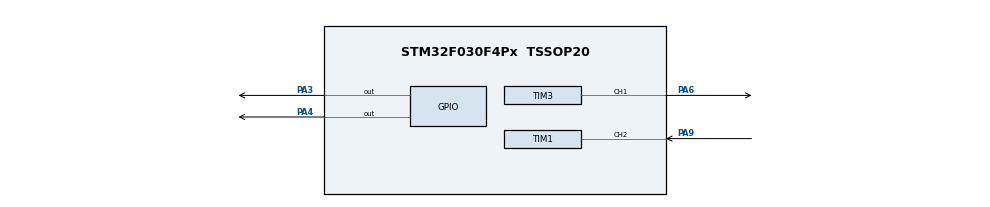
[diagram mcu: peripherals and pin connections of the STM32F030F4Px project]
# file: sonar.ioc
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Mcu.Family=STM32F0
Mcu.Name=STM32F030F4Px
Mcu.Package=TSSOP20
NVIC.TIM1_CC_IRQn=true\:0\:0\:false\:false\:true\:true
NVIC.TIM3_IRQn=true\:0\:0\:false\:false\:true\:true
PA3.Signal=GPIO_Output
PA4.Signal=GPIO_Output
PA6.Signal=S_TIM3_CH1
PA9.Signal=S_TIM1_CH2
ProjectManager.HeapSize=0x200
ProjectManager.StackSize=0x400
ProjectManager.TargetToolchain=SW4STM32
SH.S_TIM1_CH2.0=TIM1_CH2,PWM_Input_2
SH.S_TIM3_CH1.0=TIM3_CH1,PWM Generation1 CH1
TIM1.ICPolarity_1=TIM_INPUTCHANNELPOLARITY_FALLING
TIM1.Period=60000
TIM1.Prescaler=8
TIM3.Channel-PWM\ Generation1\ CH1=TIM_CHANNEL_1
TIM3.Period=40000
TIM3.Prescaler=8
TIM3.Pulse-PWM\ Generation1\ CH1=10
board=sonar

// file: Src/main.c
/**
  ******************************************************************************
  * File Name          : main.c
  * Description        : Main program body
  ******************************************************************************
  ** This notice applies to any and all portions of this file
  * that are not between comment pairs USER CODE BEGIN and
  * USER CODE END. Other portions of this file, whether
  * inserted by the user or by software development tools
  * are owned by their respective copyright owners.
  *
  * COPYRIGHT(c) 2017 STMicroelectronics
  *
  * Redistribution and use in source and binary forms, with or without modification,
  * are permitted provided that the following conditions are met:
  *   1. Redistributions of source code must retain the above copyright notice,
  *      this list of conditions and the following disclaimer.
  *   2. Redistributions in binary form must reproduce the above copyright notice,
  *      this list of conditions and the following disclaimer in the documentation
  *      and/or other materials provided with the distribution.
  *   3. Neither the name of STMicroelectronics nor the names of its contributors
  *      may be used to endorse or promote products derived from this software
  *      without specific prior written permission.
  *
  * THIS SOFTWARE IS PROVIDED BY THE COPYRIGHT HOLDERS AND CONTRIBUTORS "AS IS"
  * AND ANY EXPRESS OR IMPLIED WARRANTIES, INCLUDING, BUT NOT LIMITED TO, THE
  * IMPLIED WARRANTIES OF MERCHANTABILITY AND FITNESS FOR A PARTICULAR PURPOSE ARE
  * DISCLAIMED. IN NO EVENT SHALL THE COPYRIGHT HOLDER OR CONTRIBUTORS BE LIABLE
  * FOR ANY DIRECT, INDIRECT, INCIDENTAL, SPECIAL, EXEMPLARY, OR CONSEQUENTIAL
  * DAMAGES (INCLUDING, BUT NOT LIMITED TO, PROCUREMENT OF SUBSTITUTE GOODS OR
  * SERVICES; LOSS OF USE, DATA, OR PROFITS; OR BUSINESS INTERRUPTION) HOWEVER
  * CAUSED AND ON ANY THEORY OF LIABILITY, WHETHER IN CONTRACT, STRICT LIABILITY,
  * OR TORT (INCLUDING NEGLIGENCE OR OTHERWISE) ARISING IN ANY WAY OUT OF THE USE
  * OF THIS SOFTWARE, EVEN IF ADVISED OF THE POSSIBILITY OF SUCH DAMAGE.
  *
  ******************************************************************************
  */

#include "main.h"
#include "stm32f0xx_hal.h"

TIM_HandleTypeDef htim1;
TIM_HandleTypeDef htim3;

/* USER CODE BEGIN PV */
/* Private variables ---------------------------------------------------------*/
__IO uint32_t sensorValue = 0;
/* USER CODE END PV */

void SystemClock_Config(void);
static void MX_GPIO_Init(void);
static void MX_TIM3_Init(void);
static void MX_TIM1_Init(void);

void HAL_TIM_MspPostInit(TIM_HandleTypeDef *htim);

/* USER CODE BEGIN PFP */
/* Private function prototypes -----------------------------------------------*/

/* USER CODE END PFP */

/* USER CODE BEGIN 0 */
void HAL_TIM_IC_CaptureCallback(TIM_HandleTypeDef *htim)
{
	if(htim->Channel==HAL_TIM_ACTIVE_CHANNEL_1) {
		sensorValue=HAL_TIM_ReadCapturedValue(htim, TIM_CHANNEL_1);
	}
}
/* USER CODE END 0 */

int main(void)
{

  /* MCU Configuration----------------------------------------------------------*/

  /* Reset of all peripherals, Initializes the Flash interface and the Systick. */
  HAL_Init();

  /* Configure the system clock */
  SystemClock_Config();

  /* Initialize all configured peripherals */
  MX_GPIO_Init();
  MX_TIM3_Init();
  MX_TIM1_Init();

  /* USER CODE BEGIN 2 */
  HAL_TIM_PWM_Start(&htim3, TIM_CHANNEL_1);

  HAL_TIM_IC_Start_IT(&htim1,TIM_CHANNEL_1);
  HAL_TIM_IC_Start_IT(&htim1,TIM_CHANNEL_2);
  /* USER CODE END 2 */

  /* Infinite loop */
  /* USER CODE BEGIN WHILE */
  uint32_t tick_start=HAL_GetTick();

  while (1)
  {
	  uint32_t distance = sensorValue/58;

	  if(distance<100 && HAL_GetTick()-tick_start>distance*10) {
		  HAL_GPIO_TogglePin(GPIOA,GPIO_PIN_3);
		  tick_start=HAL_GetTick();
	  }

  /* USER CODE END WHILE */

  }

}

/** System Clock Configuration
*/
void SystemClock_Config(void)
{

  RCC_OscInitTypeDef RCC_OscInitStruct;
  RCC_ClkInitTypeDef RCC_ClkInitStruct;

    /**Initializes the CPU, AHB and APB busses clocks
    */
  RCC_OscInitStruct.OscillatorType = RCC_OSCILLATORTYPE_HSI;
  RCC_OscInitStruct.HSIState = RCC_HSI_ON;
  RCC_OscInitStruct.HSICalibrationValue = 16;
  RCC_OscInitStruct.PLL.PLLState = RCC_PLL_NONE;
  if (HAL_RCC_OscConfig(&RCC_OscInitStruct) != HAL_OK)
  {
    _Error_Handler(__FILE__, __LINE__);
  }

    /**Initializes the CPU, AHB and APB busses clocks
    */
  RCC_ClkInitStruct.ClockType = RCC_CLOCKTYPE_HCLK|RCC_CLOCKTYPE_SYSCLK
                              |RCC_CLOCKTYPE_PCLK1;
  RCC_ClkInitStruct.SYSCLKSource = RCC_SYSCLKSOURCE_HSI;
  RCC_ClkInitStruct.AHBCLKDivider = RCC_SYSCLK_DIV1;
  RCC_ClkInitStruct.APB1CLKDivider = RCC_HCLK_DIV1;

  if (HAL_RCC_ClockConfig(&RCC_ClkInitStruct, FLASH_LATENCY_0) != HAL_OK)
  {
    _Error_Handler(__FILE__, __LINE__);
  }

    /**Configure the Systick interrupt time
    */
  HAL_SYSTICK_Config(HAL_RCC_GetHCLKFreq()/1000);

    /**Configure the Systick
    */
  HAL_SYSTICK_CLKSourceConfig(SYSTICK_CLKSOURCE_HCLK);

  /* SysTick_IRQn interrupt configuration */
  HAL_NVIC_SetPriority(SysTick_IRQn, 0, 0);
}

/* TIM1 init function */
static void MX_TIM1_Init(void)
{

  TIM_SlaveConfigTypeDef sSlaveConfig;
  TIM_IC_InitTypeDef sConfigIC;
  TIM_MasterConfigTypeDef sMasterConfig;

  htim1.Instance = TIM1;
  htim1.Init.Prescaler = 8;
  htim1.Init.CounterMode = TIM_COUNTERMODE_UP;
  htim1.Init.Period = 60000;
  htim1.Init.ClockDivision = TIM_CLOCKDIVISION_DIV1;
  htim1.Init.RepetitionCounter = 0;
  htim1.Init.AutoReloadPreload = TIM_AUTORELOAD_PRELOAD_DISABLE;
  if (HAL_TIM_IC_Init(&htim1) != HAL_OK)
  {
    _Error_Handler(__FILE__, __LINE__);
  }

  sSlaveConfig.SlaveMode = TIM_SLAVEMODE_RESET;
  sSlaveConfig.InputTrigger = TIM_TS_TI2FP2;
  sSlaveConfig.TriggerPolarity = TIM_INPUTCHANNELPOLARITY_RISING;
  sSlaveConfig.TriggerPrescaler = TIM_ICPSC_DIV1;
  sSlaveConfig.TriggerFilter = 0;
  if (HAL_TIM_SlaveConfigSynchronization(&htim1, &sSlaveConfig) != HAL_OK)
  {
    _Error_Handler(__FILE__, __LINE__);
  }

  sConfigIC.ICPolarity = TIM_INPUTCHANNELPOLARITY_FALLING;
  sConfigIC.ICSelection = TIM_ICSELECTION_INDIRECTTI;
  sConfigIC.ICPrescaler = TIM_ICPSC_DIV1;
  sConfigIC.ICFilter = 0;
  if (HAL_TIM_IC_ConfigChannel(&htim1, &sConfigIC, TIM_CHANNEL_1) != HAL_OK)
  {
    _Error_Handler(__FILE__, __LINE__);
  }

  sConfigIC.ICPolarity = TIM_INPUTCHANNELPOLARITY_RISING;
  sConfigIC.ICSelection = TIM_ICSELECTION_DIRECTTI;
  if (HAL_TIM_IC_ConfigChannel(&htim1, &sConfigIC, TIM_CHANNEL_2) != HAL_OK)
  {
    _Error_Handler(__FILE__, __LINE__);
  }

  sMasterConfig.MasterOutputTrigger = TIM_TRGO_RESET;
  sMasterConfig.MasterSlaveMode = TIM_MASTERSLAVEMODE_DISABLE;
  if (HAL_TIMEx_MasterConfigSynchronization(&htim1, &sMasterConfig) != HAL_OK)
  {
    _Error_Handler(__FILE__, __LINE__);
  }

}

/* TIM3 init function */
static void MX_TIM3_Init(void)
{

  TIM_MasterConfigTypeDef sMasterConfig;
  TIM_OC_InitTypeDef sConfigOC;

  htim3.Instance = TIM3;
  htim3.Init.Prescaler = 8;
  htim3.Init.CounterMode = TIM_COUNTERMODE_UP;
  htim3.Init.Period = 40000;
  htim3.Init.ClockDivision = TIM_CLOCKDIVISION_DIV1;
  htim3.Init.AutoReloadPreload = TIM_AUTORELOAD_PRELOAD_DISABLE;
  if (HAL_TIM_PWM_Init(&htim3) != HAL_OK)
  {
    _Error_Handler(__FILE__, __LINE__);
  }

  sMasterConfig.MasterOutputTrigger = TIM_TRGO_RESET;
  sMasterConfig.MasterSlaveMode = TIM_MASTERSLAVEMODE_DISABLE;
  if (HAL_TIMEx_MasterConfigSynchronization(&htim3, &sMasterConfig) != HAL_OK)
  {
    _Error_Handler(__FILE__, __LINE__);
  }

  sConfigOC.OCMode = TIM_OCMODE_PWM1;
  sConfigOC.Pulse = 10;
  sConfigOC.OCPolarity = TIM_OCPOLARITY_HIGH;
  sConfigOC.OCFastMode = TIM_OCFAST_DISABLE;
  if (HAL_TIM_PWM_ConfigChannel(&htim3, &sConfigOC, TIM_CHANNEL_1) != HAL_OK)
  {
    _Error_Handler(__FILE__, __LINE__);
  }

  HAL_TIM_MspPostInit(&htim3);

}

/** Configure pins as
        * Analog
        * Input
        * Output
        * EVENT_OUT
        * EXTI
*/
static void MX_GPIO_Init(void)
{

  GPIO_InitTypeDef GPIO_InitStruct;

  /* GPIO Ports Clock Enable */
  __HAL_RCC_GPIOA_CLK_ENABLE();

  /*Configure GPIO pin Output Level */
  HAL_GPIO_WritePin(GPIOA, GPIO_PIN_3|GPIO_PIN_4, GPIO_PIN_RESET);

  /*Configure GPIO pins : PA3 PA4 */
  GPIO_InitStruct.Pin = GPIO_PIN_3|GPIO_PIN_4;
  GPIO_InitStruct.Mode = GPIO_MODE_OUTPUT_PP;
  GPIO_InitStruct.Pull = GPIO_NOPULL;
  GPIO_InitStruct.Speed = GPIO_SPEED_FREQ_LOW;
  HAL_GPIO_Init(GPIOA, &GPIO_InitStruct);

}

void _Error_Handler(char * file, int line)
{
  while(1)
  {
  }
}

/************************ (C) COPYRIGHT STMicroelectronics *****END OF FILE****/
